AUTOSAR XML (schema 4-2-2)
package /AUTOLIV/SoftwareComponents/IoHwAb
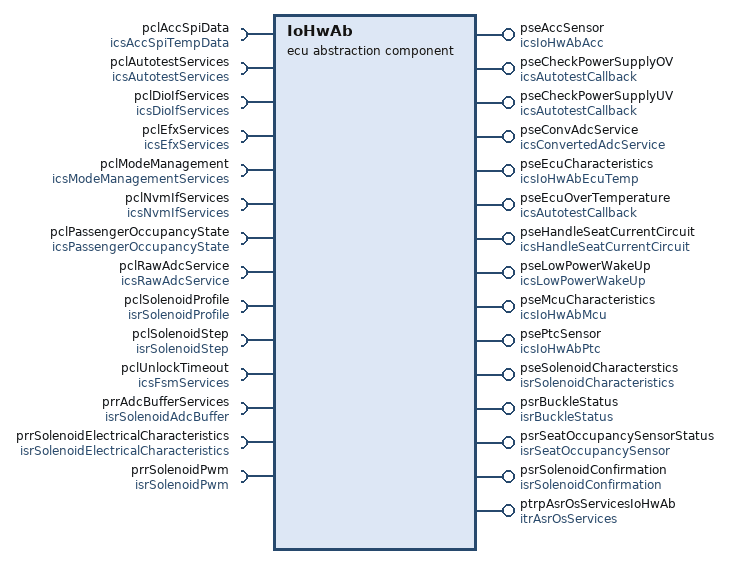
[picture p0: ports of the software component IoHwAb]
  ecu abstraction sw component type IoHwAb: category=ECU_HW_Abstraction
    14 x require port:
      pclAccSpiData: client-com-spec=GetTemperatureData, required-interface=icsAccSpiTempData  # # Architecture Element ID - ARCH_SW_IoHwAb_pclAccSpiData # Description - The interface shall read the {Raw Accelerometer Temperature} from the SPI bus according to the TDK accelerometer data-sheet # Data Flow ## Inputs - {Raw Accelerometer Temperature} # Linked Runnable - IoHwAb_GetAccelerometerTemperature #Traceability
      pclAutotestServices: required-com-specs=[GetCriticalAutoTestsReachedFlag, GetTestResult], required-interface=icsAutotestServices  # # Architecture Element ID - ARCH_SW_IoHwAb_pclAutotestServices_IoHwAb_CheckEcuOverTemperatureAutotest # Description - The interface shall return the {Auto-test Result} for the selected {Auto-test ID} # Data Flow ## Inputs - {Auto-test ID} ## Outputs - {Auto-test Result} # Linked Runnable - IoHwAb_CheckEcuOverTemperatureAutotest #Traceability DOM_eCS_TF_H_106, DOM_eCS_TF_H_107, DOM_eCS_TF_H_110, DOM_eCS_TF_H_114, DOM_eCS_TF_H_111 #------------------------------------------------------------------------------------------------------------------------------- # Architecture Element ID - ARCH_SW_IoHwAb_pclAutotestServices_IoHwAb_CheckPowerSupplyOvervoltageAutotest # Description - The interface shall return the {Auto-test Result} for the selected {Auto-test ID} # Data Flow ## Inputs - {Auto-test ID} ## Outputs - {Auto-test Result} # Linked Runnable - IoHwAb_CheckPowerSupplyOvervoltageAutotest #Traceability DOM_eCS_TF_H_269, DOM_eCS_TF_H_91, DOM_eCS_TF_H_92, DOM_eCS_TF_H_95, DOM_eCS_TF_H_96 #------------------------------------------------------------------------------------------------------------------------------- # Architecture Element ID - ARCH_SW_IoHwAb_pclAutotestServices_IoHwAb_CheckPowerSupplyUndervoltageAutotest # Description - The interface shall return the {Auto-test Result} for the selected {Auto-test ID} # Data Flow ## Inputs - {Auto-test ID} ## Outputs - {Auto-test Result} # Linked Runnable - IoHwAb_CheckPowerSupplyUndervoltageAutotest #Traceability DOM_eCS_TF_H_269, DOM_eCS_TF_H_85, DOM_eCS_TF_H_86, DOM_eCS_TF_H_66, DOM_eCS_TF_H_67 #-------------------------------------------------------------------------------------------------------------------------------
      pclDioIfServices: required-com-specs=[ReadChannel, WriteChannel], required-interface=icsDioIfServices  # # Architecture Element ID - ARCH_SW_IoHwAb_pclDioIfServices_IoHwAb_HandleSeatCurrentCircuit # Description - The interface shall write the {Wake_Channel_1 value} and {Wake_Channel_2 value} in order to detect valid state of seat occupancy. # Data Flow ## Inputs - {Wake_Channel_1 value} - {Wake_Channel_2 value} # Linked Runnable - IoHwAb_HandleSeatCurrentCircuit #Traceability
      pclEfxServices: client-com-spec=LPF_Filter, required-interface=icsEfxServices  # # Architecture Element ID - ARCH_SW_IoHwAb_pclEfxServices_IoHwAb_runFilterMeasurements10ms # Description - The interface shall read the {Instantaneous value} and filter it via a first order low pass filter # Data Flow ## Inputs - {Instantaneous value} ## Outputs - {Filtered value} # Linked Runnable - IoHwAb_runFilterMeasurements10ms #Traceability # ---------------------------------------------------------------------------------------------------------- # Architecture Element ID - ARCH_SW_IoHwAb_pclEfxServices_IoHwAb_runFilterMeasurements100ms # Description - The interface shall read the {Instantaneous value} and filter it via a first order low pass filter # Data Flow ## Inputs - {Instantaneous value} ## Outputs - {Filtered value} # Linked Runnable - IoHwAb_runFilterMeasurements100ms #Traceability
      pclModeManagement: client-com-spec=CheckModeStatus, required-interface=icsModeManagementServices  # # Architecture Element ID ARCH_SW_IoHwAb_pclModeManagement # Description - The interface shall be used to read different statuses regarding the solenoid states by passing the {Mode Status Flag} to the input parameter and reading the {Mode Status} output parameter. # Data Flow ## Inputs - {Mode Status Flag} • Can be: - CRITICAL_AUTOTESTS_IN_PROGRESS; - NVM_BLOCK_RESTORE_IN_PROGRESS; - SOLENOID_X_DISABLED; - SOLENOID_X_BUCKLE_LATCHED; - SOLENOID_X_UNLOCK_CONFIRMED; - ECU_PERMANENT_HW_ERROR; - ECU_SPORADIC_ERROR; - CAN_INHIB_STATUS; * Where X represents the solenoid number and can take the value between [1..6]; ## Outputs - {Mode Status} • Can be TRUE, FALSE #Linked Runnable - SAD_runMainFunction # Traceability
      pclNvmIfServices: required-interface=icsNvmIfServices  # # Architecture Element ID ARCH_SW_IoHwAb_pclNvmIfServices_SetRamBlockStatus # Description - The interface shall be used to set the status of a RAM Block. # Data Flow ## Inputs: - {Block Id} - {Block Status} ## Outputs: - None # Linked Runnable - IoHwAb_runFilterMeasurements10ms #Traceability
        required-com-specs:
          GetNvmBlockLength
          GetNvmBlockStatus
          ReadBlockByAddress
          RestorePRAMBlockDefaults
          SetRamBlockStatus
          WriteBlockByAddress
          WriteNvmBlock
      pclPassengerOccupancyState: client-com-spec=BswM_UpdatePassangerOccupancyStatus, required-interface=icsPassengerOccupancyState  # # Architecture Element ID - ARCH_SW_IoHwAb_pclPassengerOccupancyState # Description - The interface shall set the status of PassangerOccupancy state. # Data Flow ## Inputs: - {State of passenger occupancy} - PASSENGER_DETECTED ## Outputs: - None # Linked Runnable - IoHwAb_HandleSeatVariants # Traceability
      pclRawAdcService: client-com-spec=getChannelValue, required-interface=icsRawAdcService  # # Architecture Element ID - ARCH_SW_IoHwAb_pclRawAdcService_IoHwAb_runGetMeasure # Description - The interface shall read the {Raw value} in LSB in order to compute the value in physical units # Data Flow ## Inputs - {Raw value} # Linked Runnable - IoHwAb_runGetMeasure #Traceability #----------------------------------------------------------------------------------------------------------------------------- # Architecture Element ID ARCH_SW_IoHwAb_pclRawAdcService_IoHwAb_runFilterMeasurements10ms # Description - The interface shall read the {Raw value} in LSB in order to compute the value in physical units # Data Flow ## Inputs - {Adc channel} ## Outputs - {Adc value} # Linked Runnable - IoHwAb_runFilterMeasurements10ms # Traceability #---------------------------------------------------------------------------------------------------------------------------------- # Architecture Element ID ARCH_SW_IoHwAb_pclRawAdcService_IoHwAb_runFilterMeasurements100ms # Description - The interface shall read the {Raw value} in LSB in order to compute the value in physical units # Data Flow ## Inputs - {Adc channel} ## Outputs - {Adc value} # Linked Runnable - IoHwAb_runFilterMeasurements100ms # Traceability #---------------------------------------------------------------------------------------------------------------------------------- # Architecture Element ID ARCH_SW_IoHwAb_pclRawAdcService_IoHwAb_GetMcuTemperature # Description - The interface shall read the {Raw value} in LSB in order to compute the value in physical units # Data Flow ## Inputs - {Adc channel} ## Outputs - {Adc value} # Linked Runnable - IoHwAb_GetMcuTemperature # Traceability #---------------------------------------------------------------------------------------------------------------------------------- # Architecture Element ID ARCH_SW_IoHwAb_pclRawAdcService_IoHwAb_GetPtcTemperature # Description - The interface shall read the {Raw value} in LSB in order to compute the value in physical units # Data Flow ## Inputs - {Adc channel} ## Outputs - {Adc value} # Linked Runnable - IoHwAb_GetPtcTemperature # Traceability
      pclSolenoidProfile: nonqueued-receiver-com-spec{data-element=au8SelectedProfile, enable-update=true, init-value=6 x KU8_PROFILE_UNLOCK}, required-interface=isrSolenoidProfile  # # Architecture Element ID - ARCH_SW_IoHwAb_pclSolenoidProfile # Description - The runnable shall read the currently executed {Solenoid Profile} that is set by the Application in order to be able to start the unlock confirmation detection algorithm # Data Flow ## Inputs - {Solenoid Profile} # Linked Runnable - IoHwAb_runGetMeasure #Traceability
      pclSolenoidStep: nonqueued-receiver-com-spec{data-element=au8CurrentStep, enable-update=true, init-value=6 x 0}, required-interface=isrSolenoidStep  # # Architecture Element ID - ARCH_SW_IoHwAb_pclSolenoidStep # Description - The runnable shall read the currently executed {Solenoid Step} that is set by the Application (SAD module) in order to be able to start the unlock confirmation detection algorithm. # Data Flow ## Inputs - {Solenoid Step} # Linked Runnable - IoHwAb_DetectVoltageFluctuation #Traceability
      pclUnlockTimeout: client-com-spec=getUnlockTimeoutPeriod, required-interface=icsFsmServices  # # Architecture Element ID - ARCH_SW_IoHwAb_pclUnlockTimeout # Description - The interface shall provide unlock timeout when unlock profile is active. # Data Flow ## Inputs - NONE # Linked Runnable - iohwab_DetectVoltageFluctuationOnSolenoid #Traceability
      prrAdcBufferServices: required-interface=isrSolenoidAdcBuffer  # # Architecture Element ID - ARCH_SW_IoHwAb_prrAdcBufferServices_IoHwAb_DetectVoltageFluctuation # Description - The interface shall read the {Raw value} from AdcIf in LSB in order to determine if solenoid has been confirmed or not. - In order to read from coresponding positions, the interface shall also carry the last written position. # Data Flow ## Inputs - {Raw value} # Linked Runnable - IoHwAb_DetectVoltageFluctuation #Traceability
        required-com-specs:
          data-element=aau16HistoricalAdcSamples, enable-update=true, init-value=[aau16HistoricalAdcSamplesType_Appl_0:6 x 0, aau16HistoricalAdcSamplesType_Appl_1:6 x 0, aau16HistoricalAdcSamplesType_Appl_2:6 x 0, aau16HistoricalAdcSamplesType_Appl_3:6 x 0, aau16HistoricalAdcSamplesType_Appl_4:6 x 0, aau16HistoricalAdcSamplesType_Appl_5:6 x 0]
          data-element=u8HistoricalAdcSampleIndex, enable-update=true, init-value=0
      prrSolenoidElectricalCharacteristics: nonqueued-receiver-com-spec{data-element=au32SolenoidmATarget, enable-update=true, init-value=6 x 0}, required-interface=isrSolenoidElectricalCharacteristics  # # Architecture Element ID - ARCH_SW_IoHwAb_prrSolenoidElectricalCharacteristics_IoHwAb_runGetMeasure # Description - The interface shall read the {Solenoid PWM} that is set in the Application in order to compute the current # Data Flow ## Inputs - {Solenoid PWM} # Linked Runnable - IoHwAb_runGetMeasure #Traceability
      prrSolenoidPwm: nonqueued-receiver-com-spec{data-element=au16Pwm, enable-update=true, init-value=6 x 0}, required-interface=isrSolenoidPwm  # # Architecture Element ID - ARCH_SW_IoHwAb_prrSolenoidPwm_IoHwAb_runGetMeasure # Description - The interface shall read the {Solenoid PWM} that is set in the Application in order to compute the current # Data Flow ## Inputs - {Solenoid PWM} # Linked Runnable - IoHwAb_runGetMeasure #Traceability
    15 x provide port:
      pseAccSensor: server-com-spec{operation=GetTemperature, queue-length=1}, provided-interface=icsIoHwAbAcc  # # Architecture Element ID - ARCH_SW_IoHwAb_pseAccSensor # Description - The runnable shall read the {Raw Accelerometer Temperature} from the SPI bus and convert it to *C # Data Flow ## Inputs - {Raw Accelerometer Temperature} ## Outputs - {Accelerometer Temperature *C} - Unit: *C - Valid range: -40; +125 # Linked Runnable - IoHwAb_GetAccelerometerTemperature #Traceability FUSA_DS_ACC_6604461_000_OCD_174
      pseCheckPowerSupplyOV: server-com-spec{operation=AutotestCallback, queue-length=1}, provided-interface=icsAutotestCallback  # # Architecture Element ID - ARCH_SW_IoHwAb_pseCheckPowerSupplyOV # Description - The auto-test shall read the {KL30 Supply Voltage} and compare it to the {NVP_u16OverKL30QualificationThrs} threshold from the NvM memory - Comparison shall be done in mV - If the {Adc Auto-test Result} is NOK then the comparison cannot be done and the {Autotest Result} must be NOK - If the {KL 30 Supply Voltage} is greater than {NVP_u16OverKL30QualificationThrs} then the {Autotest Result} must be NOK - If the If the {KL 30 Supply Voltage} is lower or equal than {NVP_u16OverKL30QualificationThrs} then the {Autotest Result} must be OK # Data Flow ## Inputs - {NVP_u16OverKL30QualificationThrs} - {KL30 Supply Voltage} - {Adc Auto-test Result} ## Outputs - {Autotest Result} - Can be one of the following values: OK, NOK, NOT DECIDED # Linked Runnable - IoHwAb_CheckPowerSupplyOvervoltageAutotest #Traceability DOM_eCS_TF_H_94
      pseCheckPowerSupplyUV: server-com-spec{operation=AutotestCallback, queue-length=1}, provided-interface=icsAutotestCallback  # # Architecture Element ID - ARCH_SW_IoHwAb_pseCheckPowerSupplyUV # Description - The auto-test shall read the {KL30 Supply Voltage} and compare it to the {NVP_u16UnderKL30QualificationThrs} threshold from the NvM memory - Comparison shall be done in mV - If the {Adc Auto-test Result} is NOK then the comparison cannot be done and the {Autotest Result} must be NOK - If the {KL 30 Supply Voltage} is lower or equal to {NVP_u16UnderKL30QualificationThrs} then the {Autotest Result} must be NOK - If the If the {KL 30 Supply Voltage} is greater than {NVP_u16UnderKL30QualificationThrs} then the {Autotest Result} must be OK # Data Flow ## Inputs - {NVP_u16UnderKL30QualificationThrs} - {KL30 Supply Voltage} - {Adc Auto-test Result} ## Outputs - {Autotest Result} - Can be one of the following values: OK, NOK, NOT DECIDED # Linked Runnable - IoHwAb_CheckPowerSupplyUndervoltageAutotest #Traceability DOM_eCS_TF_H_64
      pseConvAdcService: server-com-spec{operation=getMeasure, queue-length=1}, provided-interface=icsConvertedAdcService  # # Architecture Element ID - ARCH_SW_IoHwAb_pseConvAdcService # Description - The runnable shall read the {Raw value} in LSB via the AdcIf_runGetChannelValue interface for the selected {Measurement Index} - The runnable must convert the {Raw value} input parameter to the respective unit on the {Measurement} output parameter for the the following channels: - KL30 (V_BAT): mV - MAG_V_1: mV - MAG_V_2: mV - MAG_V_3: mV - MAG_V_4: mV - MAG_V_5: mV - MAG_V_6: mV - MAG_I_1: mA - MAG_I_2: mA - MAG_I_3: mA - MAG_I_4: mA - MAG_I_5: mA - MAG_I_6: mA - MAG_V_1_10ms: mV (filtered on 10ms) - MAG_V_2_10ms: mV (filtered on 10ms) - MAG_V_3_10ms: mV (filtered on 10ms) - MAG_V_4_10ms: mV (filtered on 10ms) - MAG_V_5_10ms: mV (filtered on 10ms) - MAG_V_6_10ms: mV (filtered on 10ms) - MAG_V_1_100ms: mV (filtered on 100ms) - MAG_V_2_100ms: mV (filtered on 100ms) - MAG_V_3_100ms: mV (filtered on 100ms) - MAG_V_4_100ms: mV (filtered on 100ms) - MAG_V_5_100ms: mV (filtered on 100ms) - MAG_V_6_100ms: mV (filtered on 100ms) # Data Flow ## Inputs - {Measurement Index} - {Raw value} ## Outputs - {Measurement} # Linked Runnable - IoHwAb_runGetMeasure #Traceability
      pseEcuCharacteristics: server-com-spec{operation=GetTemperature, queue-length=1}, provided-interface=icsIoHwAbEcuTemp  # # Architecture Element ID - ARCH_SW_IoHwAb_pseEcuCharacteristics # Description - The runnable shall read the {MCU Sensor Temperature *C} - The runnable shall read the {Accelerometer Sensor Temperature *C} - The runnable shall read the {PTC Sensor Temperature *C} - The runnable shall read the temperature offsets from the NvM memory ({NVP_s8PtcTempOffset}, {NVP_s8McuTempOffset}, {NVP_s8AccTempOffset}) - The {ECU Temperature *C} output parameter must be computed from the three inputs with an weighted average # Data Flow ## Inputs - {MCU Sensor Temperature *C} - {Accelerometer Sensor Temperature *C} - {PTC Sensor Temperature *C} - {NVP_s8PtcTempOffset} - {NVP_s8McuTempOffset} - {NVP_s8AccTempOffset} ## Outputs - {ECU Temperature *C} - Unit: *C - Valid range: -40; +125 # Linked Runnable - IoHwAb_GetEcuTemperature #Traceability
      pseEcuOverTemperature: server-com-spec{operation=AutotestCallback, queue-length=1}, provided-interface=icsAutotestCallback  # # Architecture Element ID ARCH_SW_IoHwAb_pseEcuOverTemperature # Description - The autotest shall first check if ADC is function properly through ADC_OUT_OF_ORDER_AUTOTEST. If ADC_OUT_OF_ORDER_AUTOTEST returns a NOK result, then status of ECU_OVER_TEMPERATURE_AUTOTEST shall be set to NOT_DECIDED. - If ADC_OUT_OF_ORDER_AUTOTEST returns a OK result, than the ECU_OVER_TEMPERATURE_AUTOTEST auto-test shall read the {ECU Temperature} through the PTC sensor and compare it to the threshold from the NvM memory ({NVP_s16TemperatureSensorLowThrs} and {NVP_s16TemperatureSensorHighThrs}) - Comparison shall be done in *C - If the {ECU Temperature} is lower or equal to {NVP_s16TemperatureSensorLowThrs} then the {Autotest Result} must be NOK - If the {ECU Temperature} is greater or equal to {NVP_s16TemperatureSensorHighThrs} then the {Autotest Result} must be NOK - If the If the {ECU Temperature} is within the thresholds then the {Autotest Result} must be OK # Data Flow ## Inputs - {NVP_s16TemperatureSensorHighThrs} - {NVP_s16TemperatureSensorLowThrs} - {ECU Temperature} ## Outputs - {Autotest Result} - Can be one of the following values: OK, NOK, NOT DECIDED # Linked Runnable - IoHwAb_CheckEcuOverTemperatureAutotest #Traceability DOM_eCS_TF_H_109
      pseHandleSeatCurrentCircuit: server-com-spec{operation=IoHwAb_HandleSeatCurrentCircuit, queue-length=1}, provided-interface=icsHandleSeatCurrentCircuit  # # Architecture Element ID - ARCH_SW_IoHwAb_pseHandleSeatCurrentCircuit # Description - The runnable shall read the raw ADC level of the {Wake channel 1} and {Wake channel 2} and determine if they are valid depending on the state of the seat state detection circuit. - It will change the state the seat detection circuit if its not in a correct state # Data Flow ## Inputs - {Wake channel 1} - {Wake channel 2} - {reset stored values and circuit} ## Outputs - {Wake Up Status} - Can be B_TRUE or B_FALSE - {Last SBS State} - NvM Parameter # Linked Runnable - IoHwAb_HandleSeatCurrentCircuit - IoHwAb_runFilterMeasurements10ms #Traceability
      pseLowPowerWakeUp: server-com-spec{operation=HandleSeatVariants, queue-length=1}, provided-interface=icsLowPowerWakeUp  # # Architecture Element ID - ARCH_SW_IoHwAb_pseLowPowerWakeUp # Description - The runnable shall read the voltage level of the {Wake channel 1} and {Wake channel 2} via the input parameters - The runnable shall set the {Wake Up Status} output parameter to B_TRUE if any transition of buckle and seat sensor status is detected - The runnable shall save the {Last valid SBS status} in NvM (occupied/not occupied/short to ground(if removable seats are not configured)/unknown) # Data Flow ## Inputs - {Wake channel 1} - {Wake channel 2} ## Outputs - {Wake Up Status} - Can be B_TRUE or B_FALSE - {Last SBS State} - NvM Parameter # Linked Runnable - IoHwAb_HandleSeatVariants - IoHwAb_runFilterMeasurements10ms #Traceability
      pseMcuCharacteristics: server-com-spec{operation=GetTemperature, queue-length=1}, provided-interface=icsIoHwAbMcu  # # Architecture Element ID - ARCH_SW_IoHwAb_pseMcuCharacteristics # Description - The runnable shall read the {MCU Sensor Band Gap Voltage} and {Raw MCU Sensor Temperature} via the ADC in LSB and convert it to *C # Data Flow ## Inputs ## Outputs - {MCU Sensor Temperature *C} - Unit: *C - Valid range: -40; +125 # Linked Runnable - IoHwAb_GetMcuTemperature #Traceability
      psePtcSensor: server-com-spec{operation=GetTemperature, queue-length=1}, provided-interface=icsIoHwAbPtc  # # Architecture Element ID - ARCH_SW_IoHwAb_psePtcSensor # Description - The runnable shall read the {Raw PTC Sensor Temperature} via the AdcIf_runGetChannelValue interface in LSB and convert it to *C # Data Flow ## Inputs - {Raw PTC Sensor Temperature} ## Outputs - {PTC Sensor Temperature *C} - Unit: *C - Valid range: -40; +125 # Linked Runnable - IoHwAb_GetPtcTemperature #Traceability
      pseSolenoidCharacterstics: server-com-spec{operation=GetTemperature, queue-length=1}, provided-interface=isrSolenoidCharacteristics  # # Architecture Element ID - ARCH_SW_IoHwAb_pseSolenoidCharacterstics # Description - The runnable shall read the {Filtered Voltage Solenoid 100ms} for the selected solenoid on the {Solenoid Index} input parameter - The runnable shall read the {Current Solenoid} for the selected solenoid on the {Solenoid Index} input parameter - The runnable must compute the temperature of the solenoid # Data Flow ## Inputs - {Solenoid Index} ## Outputs - {Solenoid Temperature *C} - Unit: *C - Valid range: -40; +125 # Linked Runnable - IoHwAb_GetSolenoidTemperature #Traceability
      psrBuckleStatus: nonqueued-sender-com-spec{data-element=au8BuckleStatus, uses-end-to-end-protection=0, init-value=[KU8_BUCKLE_LATCHED, KU8_BUCKLE_LATCHED]}, provided-interface=isrBuckleStatus  # # Architecture Element ID - ARCH_SW_IoHwAb_psrBuckleStatus # Description - The runnable shall read the raw ADC level of the {Wake channel 1} and {Wake channel 2} via the input parameters and filter them using a Low Pass FIlter every 10ms. - The runnable shall set the {Buckle Status Seat 1} and {Buckle Status Seat 2} depending on the resistance values computed from the input parameters. # Data Flow ## Inputs - {Wake channel 1} - {Wake channel 2} ## Outputs - {Buckle Status Seat 1} - Can be BUCKLE_LATCHED, BUCKLE_NOT_LATCHED, BUCKLE_STATUS_UNKNOWN - {Buckle Status Seat 2} - Can be BUCKLE_LATCHED, BUCKLE_NOT_LATCHED, BUCKLE_STATUS_UNKNOWN # Linked Runnable - IoHwAb_runFilterMeasurements10ms #Traceability
      psrSeatOccupancySensorStatus: nonqueued-sender-com-spec{data-element=au8SeatOccupancySensorStatus, uses-end-to-end-protection=0, init-value=[KU8_SEAT_OCCUPANCY_DETECTED, KU8_SEAT_OCCUPANCY_DETECTED]}, provided-interface=isrSeatOccupancySensor  # # Architecture Element ID - ARCH_SW_IoHwAb_psrSeatOccupancySensorStatus # Description - The runnable shall read the raw ADC level of the of the {Wake channel 1} and {Wake channel 2} via the input parameters and filter them using a Low Pass FIlter every 10ms. - The runnable shall set the {Seat Occupancy Status 1} and {Seat Occupancy Status 2} depending on the resistance values computed from the input parameters # Data Flow ## Inputs - {Wake channel 1} - {Wake channel 2} ## Outputs - {Seat Occupancy Status 1} - Can be SEAT_OCCUPIED, SEAT_NOT_OCCUPIED, SEAT_OCCUPANCY_UNKNOWN - {Seat Occupancy Status2} - Can be SEAT_OCCUPIED, SEAT_NOT_OCCUPIED, SEAT_OCCUPANCY_UNKNOWN # Linked Runnable - IoHwAb_runFilterMeasurements10ms #Traceability - DOM_eCS_TF_F_4, DOM_eCS_TF_F_5, DOM_eCS_TF_F_6, DOM_eCS_TF_F_7, DOM_eCS_TF_F_12, DOM_eCS_TF_F_13, DOM_eCS_TF_F_14, DOM_eCS_TF_F_15, DOM_eCS_TF_F_45, DOM_eCS_TF_F_46, DOM_eCS_TF_F_19, DOM_eCS_TF_F_21, DOM_eCS_TF_F_23, DOM_eCS_TF_F_25,DOM_eCS_TF_F_27, DOM_eCS_TF_F_29, DOM_eCS_TF_F_34, DOM_eCS_TF_F_36, DOM_eCS_TF_F_38, DOM_eCS_TF_F_41, DOM_eCS_TF_F_42, DOM_eCS_TF_F_43, DOM_eCS_TF_F_44
      psrSolenoidConfirmation: nonqueued-sender-com-spec{data-element=au8SolenoidStatus, uses-end-to-end-protection=0, init-value=6 x KU8_SOLENOID_UNLOCK_NOT_CONFIRMED}, provided-interface=isrSolenoidConfirmation  # # Architecture Element ID - ARCH_SW_IoHwAb_psrSolenoidConfirmation # Description - The runnable shall read the {Current Executed Profile} for each solenoid(can be NONE/UNLOCK/BACKUP) - The runnable shall read the {Unfiltered Voltage Solenoid} for each solenoid in mV - The runnable shall compute the {Unlock detection timeout Threshold} from the step definition of the first cycle (it will add the duration for each step that is not infinite) - If a voltage spike greater than 8V is detected in the first 6ms since the profile was launched the maximum and minimum voltage values during this period will be saved - If a voltage greater than the minimum voltage value +2V is detected than the unlock has been confirmed - If the unlock has not been confirmed until the {Unlock detection timeout Threshold} has been reached then the status will be not determined # Data Flow ## Inputs - {Current Executed Profile}[x] - {Unfiltered Voltage Solenoid}[x] - {Unlock detection timeout Threshold} ## Outputs - {Solenoid Confirmation Status}[x] - 0: NOT_DETERMINED - 1: UNLOCK_CONFIRMED # Linked Runnable - IoHwAb_DetectVoltageFluctuation #Traceability
      ptrpAsrOsServicesIoHwAb: provided-interface=itrAsrOsServices  # # Architecture Element ID ARCH_SW_BswMIf_ptrpAsrOsServicesIoHwAb_IoHwAb_runFilterMeasurements2ms # Description - The IoHwAb_runFilterMeasurements2ms runnable shall be called when the Os task {OsTask_Alv_Autotests} is executed # Data Flow # Linked Runnable - IoHwAb_runFilterMeasurements2ms # Traceability # ------------------------------------------------------------------------------------------------------------------------------------------- # Architecture Element ID ARCH_SW_BswMIf_ptrpAsrOsServicesIoHwAb_IoHwAb_runFilterMeasurements10ms # Description - The IoHwAb_runFilterMeasurements10ms runnable shall be called when the Os task {OsTask_Alv_Autotests} is executed # Data Flow # Linked Runnable - IoHwAb_runFilterMeasurements10ms # Traceability # ------------------------------------------------------------------------------------------------------------------------------------------- # Architecture Element ID ARCH_SW_BswMIf_ptrpAsrOsServicesIoHwAb_IoHwAb_runFilterMeasurements100ms # Description - The IoHwAb_runFilterMeasurements100ms runnable shall be called when the Os task {OsTask_Alv_Autotests} is executed # Data Flow # Linked Runnable - IoHwAb_runFilterMeasurements100ms # Traceability # ------------------------------------------------------------------------------------------------------------------------------------------- # Architecture Element ID ARCH_SW_BswMIf_ptrpAsrOsServicesIoHwAb_IoHwAb_DetectVoltageFluctuation # Description - The IoHwAb_DetectVoltageFluctuation runnable shall be called when the Os task {OsTask_Alv_eCS_App} is executed # Data Flow # Linked Runnable - IoHwAb_DetectVoltageFluctuation # Traceability # -------------------------------------------------------------------------------------------------------------------------------------------
